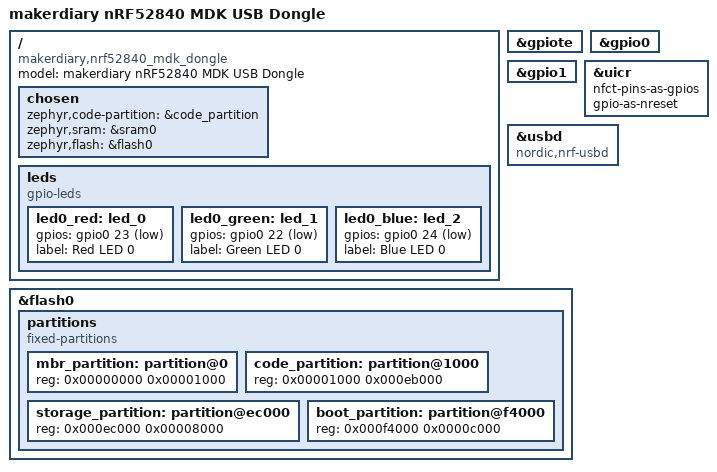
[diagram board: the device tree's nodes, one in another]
/*
 * SPDX-License-Identifier: MIT
 *
 * makerdiary nRF52840 MDK USB Dongle for ZMK (Zephyr 3.5 / ZMK v0.3 board model).
 * Zephyr's upstream nrf52840_mdk_usb_dongle board links for Nordic's nRF5
 * bootloader, so this board carries the flash layout of the stock makerdiary
 * UF2 bootloader instead (an Adafruit nRF52 bootloader fork, no SoftDevice):
 *   0x00000  MBR
 *   0x01000  application
 *   0xF4000  bootloader + its settings
 * https://wiki.makerdiary.com/nrf52840-mdk-usb-dongle/programming/uf2boot/
 */

/dts-v1/;
#include <nordic/nrf52840_qiaa.dtsi>

/ {
    model = "makerdiary nRF52840 MDK USB Dongle";
    compatible = "makerdiary,nrf52840_mdk_dongle";

    chosen {
        zephyr,code-partition = &code_partition;
        zephyr,sram = &sram0;
        zephyr,flash = &flash0;
    };

    leds {
        compatible = "gpio-leds";
        led0_red: led_0 {
            gpios = <&gpio0 23 GPIO_ACTIVE_LOW>;
            label = "Red LED 0";
        };
        led0_green: led_1 {
            gpios = <&gpio0 22 GPIO_ACTIVE_LOW>;
            label = "Green LED 0";
        };
        led0_blue: led_2 {
            gpios = <&gpio0 24 GPIO_ACTIVE_LOW>;
            label = "Blue LED 0";
        };
    };
};

&gpiote {
    status = "okay";
};

&gpio0 {
    status = "okay";
};

&gpio1 {
    status = "okay";
};

/* The side button is wired to P0.18. As nRESET, a double tap drops the stock
   bootloader into UF2BOOT without unplugging. */
&uicr {
    nfct-pins-as-gpios;
    gpio-as-nreset;
};

zephyr_udc0: &usbd {
    compatible = "nordic,nrf-usbd";
    status = "okay";
};

&flash0 {
    partitions {
        compatible = "fixed-partitions";
        #address-cells = <1>;
        #size-cells = <1>;

        mbr_partition: partition@0 {
            reg = <0x00000000 0x00001000>;
        };
        code_partition: partition@1000 {
            reg = <0x00001000 0x000eb000>;
        };
        /* NVS settings storage (BT bonds, layer state, Studio keymap). */
        storage_partition: partition@ec000 {
            reg = <0x000ec000 0x00008000>;
        };
        boot_partition: partition@f4000 {
            reg = <0x000f4000 0x0000c000>;
        };
    };
};
